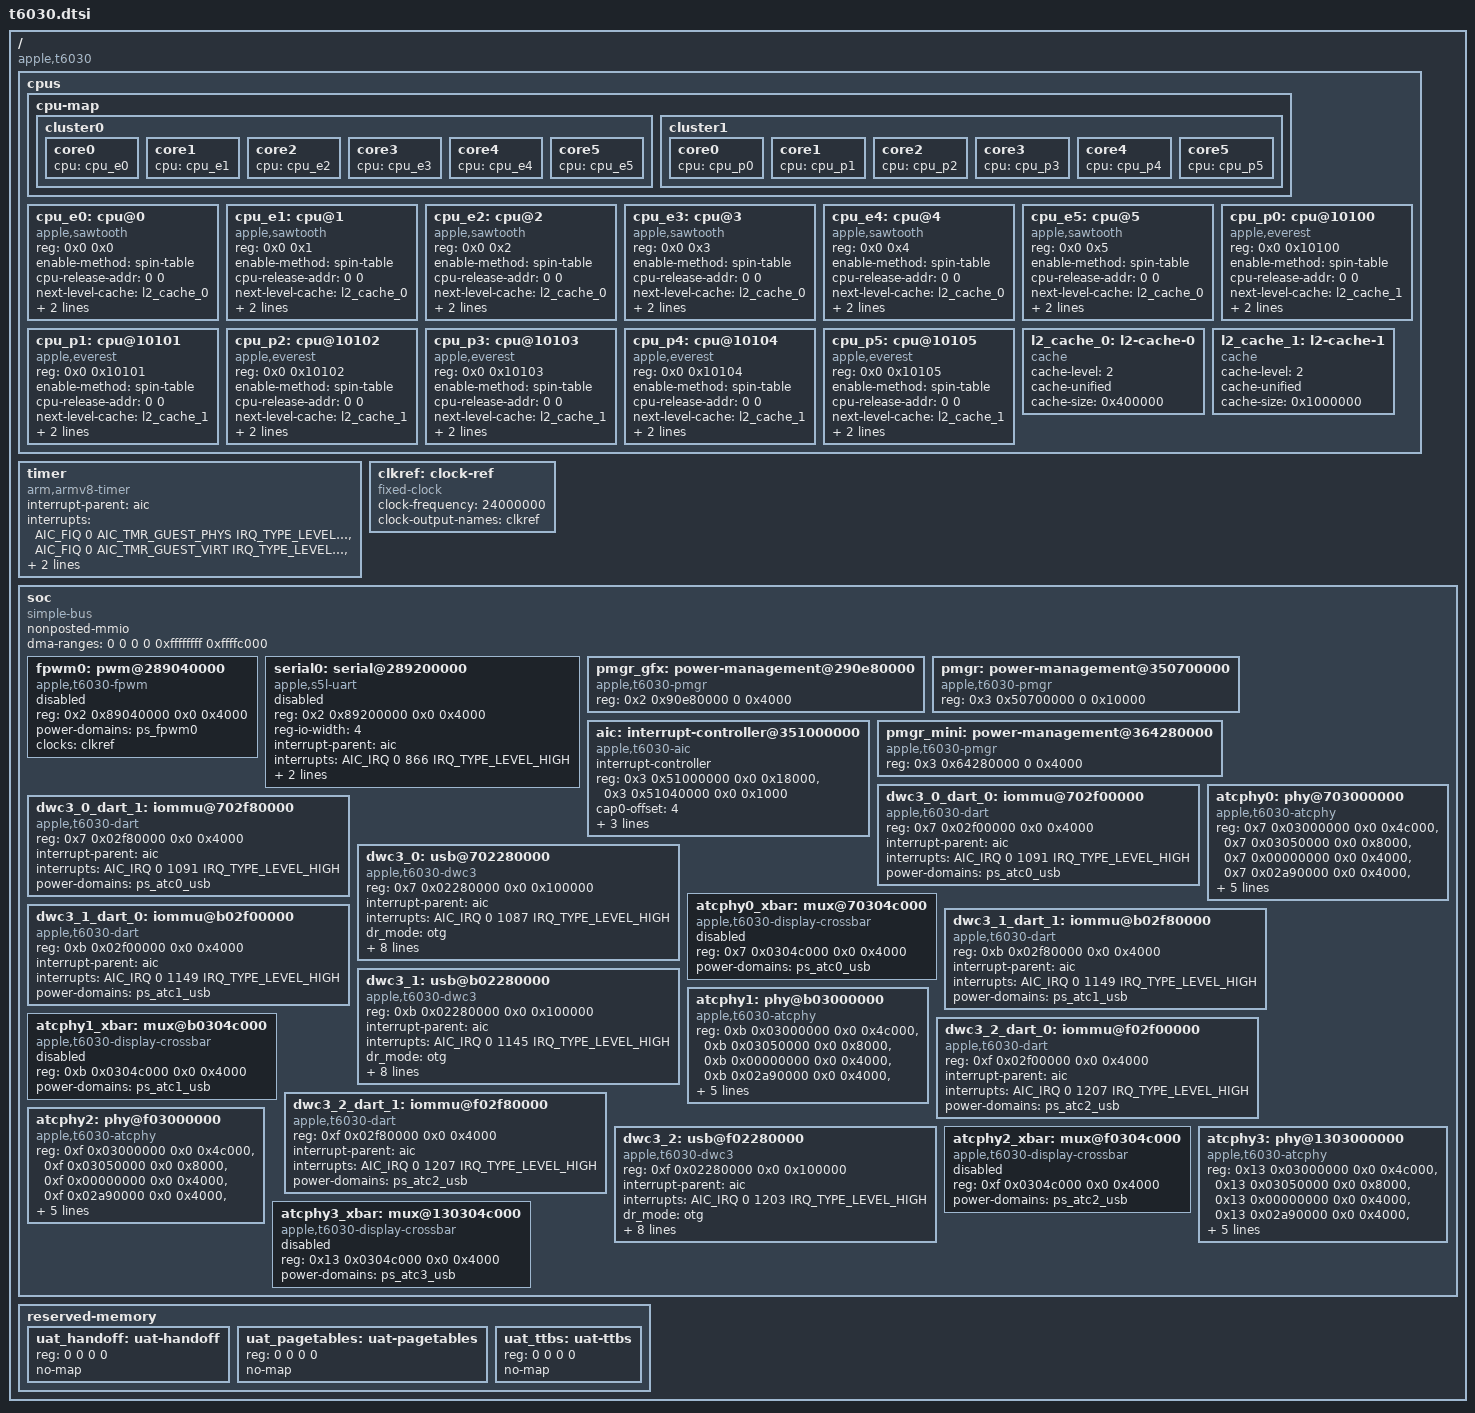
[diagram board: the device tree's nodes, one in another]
// SPDX-License-Identifier: GPL-2.0+ OR MIT
/*
 * Apple T6030 "M3 Pro" SoC
 *
 * Other names: H15J, "Lobos"
 *
 * Copyright The Asahi Linux Contributors
 */

#include <dt-bindings/interrupt-controller/apple-aic.h>
#include <dt-bindings/interrupt-controller/irq.h>
#include <dt-bindings/phy/phy.h>

#include "multi-die-cpp.h"

/ {
	compatible = "apple,t6030", "apple,arm-platform";

	#address-cells = <2>;
	#size-cells = <2>;

	cpus {
		#address-cells = <2>;
		#size-cells = <0>;

		cpu-map {
			cluster0 {
				core0 {
					cpu = <&cpu_e0>;
				};
				core1 {
					cpu = <&cpu_e1>;
				};
				core2 {
					cpu = <&cpu_e2>;
				};
				core3 {
					cpu = <&cpu_e3>;
				};
				core4 {
					cpu = <&cpu_e4>;
				};
				core5 {
					cpu = <&cpu_e5>;
				};
			};

			cluster1 {
				core0 {
					cpu = <&cpu_p0>;
				};
				core1 {
					cpu = <&cpu_p1>;
				};
				core2 {
					cpu = <&cpu_p2>;
				};
				core3 {
					cpu = <&cpu_p3>;
				};
				core4 {
					cpu = <&cpu_p4>;
				};
				core5 {
					cpu = <&cpu_p5>;
				};
			};
		};

		cpu_e0: cpu@0 {
			compatible = "apple,sawtooth";
			device_type = "cpu";
			reg = <0x0 0x0>;
			enable-method = "spin-table";
			cpu-release-addr = <0 0>; /* to be filled by loader */
			next-level-cache = <&l2_cache_0>;
			i-cache-size  = <0x20000>;
			d-cache-size = <0x10000>;
			//operating-points-v2 = <&sawtooth_opp>;
			//capacity-dmips-mhz = <756>;
			//performance-domains = <&cpufreq_e_die1>;
		};

		cpu_e1: cpu@1 {
			compatible = "apple,sawtooth";
			device_type = "cpu";
			reg = <0x0 0x1>;
			enable-method = "spin-table";
			cpu-release-addr = <0 0>; /* to be filled by loader */
			next-level-cache = <&l2_cache_0>;
			i-cache-size  = <0x20000>;
			d-cache-size = <0x10000>;
			//operating-points-v2 = <&sawtooth_opp>;
			//capacity-dmips-mhz = <756>;
			//performance-domains = <&cpufreq_e_die1>;
		};

		cpu_e2: cpu@2 {
			compatible = "apple,sawtooth";
			device_type = "cpu";
			reg = <0x0 0x2>;
			enable-method = "spin-table";
			cpu-release-addr = <0 0>; /* to be filled by loader */
			next-level-cache = <&l2_cache_0>;
			i-cache-size  = <0x20000>;
			d-cache-size = <0x10000>;
			//operating-points-v2 = <&sawtooth_opp>;
			//capacity-dmips-mhz = <756>;
			//performance-domains = <&cpufreq_e_die1>;
		};

		cpu_e3: cpu@3 {
			compatible = "apple,sawtooth";
			device_type = "cpu";
			reg = <0x0 0x3>;
			enable-method = "spin-table";
			cpu-release-addr = <0 0>; /* to be filled by loader */
			next-level-cache = <&l2_cache_0>;
			i-cache-size  = <0x20000>;
			d-cache-size = <0x10000>;
			//operating-points-v2 = <&sawtooth_opp>;
			//capacity-dmips-mhz = <756>;
			//performance-domains = <&cpufreq_e_die1>;
		};

		cpu_e4: cpu@4 {
			compatible = "apple,sawtooth";
			device_type = "cpu";
			reg = <0x0 0x4>;
			enable-method = "spin-table";
			cpu-release-addr = <0 0>; /* to be filled by loader */
			next-level-cache = <&l2_cache_0>;
			i-cache-size  = <0x20000>;
			d-cache-size = <0x10000>;
			//operating-points-v2 = <&sawtooth_opp>;
			//capacity-dmips-mhz = <756>;
			//performance-domains = <&cpufreq_e_die1>;
		};

		cpu_e5: cpu@5 {
			compatible = "apple,sawtooth";
			device_type = "cpu";
			reg = <0x0 0x5>;
			enable-method = "spin-table";
			cpu-release-addr = <0 0>; /* to be filled by loader */
			next-level-cache = <&l2_cache_0>;
			i-cache-size  = <0x20000>;
			d-cache-size = <0x10000>;
			//operating-points-v2 = <&sawtooth_opp>;
			//capacity-dmips-mhz = <756>;
			//performance-domains = <&cpufreq_e_die1>;
		};

		cpu_p0: cpu@10100 {
			compatible = "apple,everest";
			device_type = "cpu";
			reg = <0x0 0x10100>;
			enable-method = "spin-table";
			cpu-release-addr = <0 0>; /* to be filled by loader */
			next-level-cache = <&l2_cache_1>;
			i-cache-size  = <0x30000>;
			d-cache-size = <0x20000>;
			//operating-points-v2 = <&everest_opp>;
			//capacity-dmips-mhz = <756>;
			//performance-domains = <&cpufreq_e_die1>;
		};

		cpu_p1: cpu@10101 {
			compatible = "apple,everest";
			device_type = "cpu";
			reg = <0x0 0x10101>;
			enable-method = "spin-table";
			cpu-release-addr = <0 0>; /* to be filled by loader */
			next-level-cache = <&l2_cache_1>;
			i-cache-size  = <0x30000>;
			d-cache-size = <0x20000>;
			//operating-points-v2 = <&everest_opp>;
			//capacity-dmips-mhz = <756>;
			//performance-domains = <&cpufreq_e_die1>;
		};

		cpu_p2: cpu@10102 {
			compatible = "apple,everest";
			device_type = "cpu";
			reg = <0x0 0x10102>;
			enable-method = "spin-table";
			cpu-release-addr = <0 0>; /* to be filled by loader */
			next-level-cache = <&l2_cache_1>;
			i-cache-size  = <0x30000>;
			d-cache-size = <0x20000>;
			//operating-points-v2 = <&everest_opp>;
			//capacity-dmips-mhz = <756>;
			//performance-domains = <&cpufreq_e_die1>;
		};

		cpu_p3: cpu@10103 {
			compatible = "apple,everest";
			device_type = "cpu";
			reg = <0x0 0x10103>;
			enable-method = "spin-table";
			cpu-release-addr = <0 0>; /* to be filled by loader */
			next-level-cache = <&l2_cache_1>;
			i-cache-size  = <0x30000>;
			d-cache-size = <0x20000>;
			//operating-points-v2 = <&everest_opp>;
			//capacity-dmips-mhz = <756>;
			//performance-domains = <&cpufreq_e_die1>;
		};

		cpu_p4: cpu@10104 {
			compatible = "apple,everest";
			device_type = "cpu";
			reg = <0x0 0x10104>;
			enable-method = "spin-table";
			cpu-release-addr = <0 0>; /* to be filled by loader */
			next-level-cache = <&l2_cache_1>;
			i-cache-size  = <0x30000>;
			d-cache-size = <0x20000>;
			//operating-points-v2 = <&everest_opp>;
			//capacity-dmips-mhz = <756>;
			//performance-domains = <&cpufreq_e_die1>;
		};

		cpu_p5: cpu@10105 {
			compatible = "apple,everest";
			device_type = "cpu";
			reg = <0x0 0x10105>;
			enable-method = "spin-table";
			cpu-release-addr = <0 0>; /* to be filled by loader */
			next-level-cache = <&l2_cache_1>;
			i-cache-size  = <0x30000>;
			d-cache-size = <0x20000>;
			//operating-points-v2 = <&everest_opp>;
			//capacity-dmips-mhz = <756>;
			//performance-domains = <&cpufreq_e_die1>;
		};

		l2_cache_0: l2-cache-0 {
			compatible = "cache";
			cache-level = <2>;
			cache-unified;
			cache-size = <0x400000>;
		};

		l2_cache_1: l2-cache-1 {
			compatible = "cache";
			cache-level = <2>;
			cache-unified;
			cache-size = <0x1000000>;
		};
	};

	timer {
		compatible = "arm,armv8-timer";
		interrupt-parent = <&aic>;
		interrupt-names = "phys", "virt", "hyp-phys", "hyp-virt";
		interrupts = <AIC_FIQ 0 AIC_TMR_GUEST_PHYS IRQ_TYPE_LEVEL_HIGH>,
			     <AIC_FIQ 0 AIC_TMR_GUEST_VIRT IRQ_TYPE_LEVEL_HIGH>,
			     <AIC_FIQ 0 AIC_TMR_HV_PHYS IRQ_TYPE_LEVEL_HIGH>,
			     <AIC_FIQ 0 AIC_TMR_HV_VIRT IRQ_TYPE_LEVEL_HIGH>;
	};

	clkref: clock-ref {
		compatible = "fixed-clock";
		#clock-cells = <0>;
		clock-frequency = <24000000>;
		clock-output-names = "clkref";
	};

	soc {
		compatible = "simple-bus";
		#address-cells = <2>;
		#size-cells = <2>;

		ranges;
		nonposted-mmio;
		/* Required to get >32-bit DMA via DARTs */
		dma-ranges = <0 0 0 0 0xffffffff 0xffffc000>;

		fpwm0: pwm@289040000 {
			compatible = "apple,t6030-fpwm", "apple,s5l-fpwm";
			reg = <0x2 0x89040000 0x0 0x4000>;
			power-domains = <&ps_fpwm0>;
			clocks = <&clkref>;
			#pwm-cells = <2>;
			status = "disabled";
		};

		serial0: serial@289200000 {
			compatible = "apple,s5l-uart";
			reg = <0x2 0x89200000 0x0 0x4000>;
			reg-io-width = <4>;
			interrupt-parent = <&aic>;
			interrupts = <AIC_IRQ 0 866 IRQ_TYPE_LEVEL_HIGH>;
			/*
			* TODO: figure out the clocking properly, there may
			* be a third selectable clock.
			*/
			clocks = <&clkref>, <&clkref>;
			clock-names = "uart", "clk_uart_baud0";
			power-domains = <&ps_uart0>;
			status = "disabled";
		};

		pmgr_gfx: power-management@290e80000 {
			compatible = "apple,t6030-pmgr", "apple,pmgr", "syscon", "simple-mfd";
			#address-cells = <1>;
			#size-cells = <1>;
			reg = <0x2 0x90e80000 0 0x4000>;
		};

		pmgr: power-management@350700000 {
			compatible = "apple,t6030-pmgr", "apple,pmgr", "syscon", "simple-mfd";
			#address-cells = <1>;
			#size-cells = <1>;
			reg = <0x3 0x50700000 0 0x10000>;
		};

		aic: interrupt-controller@351000000 {
			compatible = "apple,t6030-aic", "apple,aic3";
			#interrupt-cells = <4>;
			interrupt-controller;
			reg = <0x3 0x51000000 0x0 0x18000>,
				  <0x3 0x51040000 0x0 0x1000>;
			reg-names = "core", "event";
			cap0-offset = <4>;
			maxnumirq-offset = <12>;
			config-offset = <0x10000>;
			power-domains = <&ps_aic>;
		};

		pmgr_mini: power-management@364280000 {
			compatible = "apple,t6030-pmgr", "apple,pmgr", "syscon", "simple-mfd";
			#address-cells = <1>;
			#size-cells = <1>;
			reg = <0x3 0x64280000 0 0x4000>;
		};

		dwc3_0_dart_0: iommu@702f00000 {
			compatible = "apple,t6030-dart", "apple,t8110-dart";
			reg = <0x7 0x02f00000 0x0 0x4000>;
			interrupt-parent = <&aic>;
			interrupts = <AIC_IRQ 0 1091 IRQ_TYPE_LEVEL_HIGH>;
			power-domains = <&ps_atc0_usb>;
			#iommu-cells = <1>;
		};

		dwc3_0_dart_1: iommu@702f80000 {
			compatible = "apple,t6030-dart", "apple,t8110-dart";
			reg = <0x7 0x02f80000 0x0 0x4000>;
			interrupt-parent = <&aic>;
			interrupts = <AIC_IRQ 0 1091 IRQ_TYPE_LEVEL_HIGH>;
			power-domains = <&ps_atc0_usb>;
			#iommu-cells = <1>;
		};

		dwc3_0: usb@702280000 {
			compatible = "apple,t6030-dwc3", "apple,dwc3", "snps,dwc3";
			reg = <0x7 0x02280000 0x0 0x100000>;
			interrupt-parent = <&aic>;
			interrupts = <AIC_IRQ 0 1087 IRQ_TYPE_LEVEL_HIGH>;
			dr_mode = "otg";
			usb-role-switch;
			role-switch-default-mode = "host";
			iommus = <&dwc3_0_dart_0 0>,
				<&dwc3_0_dart_1 1>;
			power-domains = <&ps_atc0_usb>;
			dma-coherent;
			resets = <&atcphy0>;
			maximum-speed = "high-speed";
			phys = <&atcphy0 PHY_TYPE_USB2>;
			phy-names = "usb2-phy";
		};

		atcphy0: phy@703000000 {
			compatible = "apple,t6030-atcphy", "apple,t8103-atcphy";
			reg = <0x7 0x03000000 0x0 0x4c000>,
				<0x7 0x03050000 0x0 0x8000>,
				<0x7 0x00000000 0x0 0x4000>,
				<0x7 0x02a90000 0x0 0x4000>,
				<0x7 0x02a84000 0x0 0x4000>;
			reg-names = "core", "lpdptx", "axi2af", "usb2phy",
				"pipehandler";

			#phy-cells = <1>;
			#reset-cells = <0>;

			orientation-switch;
			mode-switch;
			svid = <0xff01>, <0x8087>;
			power-domains = <&ps_atc0_usb>;
		};

		atcphy0_xbar: mux@70304c000 {
			compatible = "apple,t6030-display-crossbar";
			reg = <0x7 0x0304c000 0x0 0x4000>;
			#mux-control-cells = <1>;
			power-domains = <&ps_atc0_usb>;
			status = "disabled";
		};

		dwc3_1_dart_0: iommu@b02f00000 {
			compatible = "apple,t6030-dart", "apple,t8110-dart";
			reg = <0xb 0x02f00000 0x0 0x4000>;
			interrupt-parent = <&aic>;
			interrupts = <AIC_IRQ 0 1149 IRQ_TYPE_LEVEL_HIGH>;
			power-domains = <&ps_atc1_usb>;
			#iommu-cells = <1>;
		};

		dwc3_1_dart_1: iommu@b02f80000 {
			compatible = "apple,t6030-dart", "apple,t8110-dart";
			reg = <0xb 0x02f80000 0x0 0x4000>;
			interrupt-parent = <&aic>;
			interrupts = <AIC_IRQ 0 1149 IRQ_TYPE_LEVEL_HIGH>;
			power-domains = <&ps_atc1_usb>;
			#iommu-cells = <1>;
		};

		dwc3_1: usb@b02280000 {
			compatible = "apple,t6030-dwc3", "apple,dwc3", "snps,dwc3";
			reg = <0xb 0x02280000 0x0 0x100000>;
			interrupt-parent = <&aic>;
			interrupts = <AIC_IRQ 0 1145 IRQ_TYPE_LEVEL_HIGH>;
			dr_mode = "otg";
			usb-role-switch;
			role-switch-default-mode = "host";
			iommus = <&dwc3_1_dart_0 0>,
				<&dwc3_1_dart_1 1>;
			power-domains = <&ps_atc1_usb>;
			dma-coherent;
			resets = <&atcphy1>;
			maximum-speed = "high-speed";
			phys = <&atcphy1 PHY_TYPE_USB2>;
			phy-names = "usb2-phy";
		};

		atcphy1: phy@b03000000 {
			compatible = "apple,t6030-atcphy", "apple,t8103-atcphy";
			reg = <0xb 0x03000000 0x0 0x4c000>,
				<0xb 0x03050000 0x0 0x8000>,
				<0xb 0x00000000 0x0 0x4000>,
				<0xb 0x02a90000 0x0 0x4000>,
				<0xb 0x02a84000 0x0 0x4000>;
			reg-names = "core", "lpdptx", "axi2af", "usb2phy",
				"pipehandler";

			#phy-cells = <1>;
			#reset-cells = <0>;

			orientation-switch;
			mode-switch;
			svid = <0xff01>, <0x8087>;
			power-domains = <&ps_atc1_usb>;
		};

		atcphy1_xbar: mux@b0304c000 {
			compatible = "apple,t6030-display-crossbar";
			reg = <0xb 0x0304c000 0x0 0x4000>;
			#mux-control-cells = <1>;
			power-domains = <&ps_atc1_usb>;
			status = "disabled";
		};

		dwc3_2_dart_0: iommu@f02f00000 {
			compatible = "apple,t6030-dart", "apple,t8110-dart";
			reg = <0xf 0x02f00000 0x0 0x4000>;
			interrupt-parent = <&aic>;
			interrupts = <AIC_IRQ 0 1207 IRQ_TYPE_LEVEL_HIGH>;
			power-domains = <&ps_atc2_usb>;
			#iommu-cells = <1>;
		};

		dwc3_2_dart_1: iommu@f02f80000 {
			compatible = "apple,t6030-dart", "apple,t8110-dart";
			reg = <0xf 0x02f80000 0x0 0x4000>;
			interrupt-parent = <&aic>;
			interrupts = <AIC_IRQ 0 1207 IRQ_TYPE_LEVEL_HIGH>;
			power-domains = <&ps_atc2_usb>;
			#iommu-cells = <1>;
		};

		dwc3_2: usb@f02280000 {
			compatible = "apple,t6030-dwc3", "apple,dwc3", "snps,dwc3";
			reg = <0xf 0x02280000 0x0 0x100000>;
			interrupt-parent = <&aic>;
			interrupts = <AIC_IRQ 0 1203 IRQ_TYPE_LEVEL_HIGH>;
			dr_mode = "otg";
			usb-role-switch;
			role-switch-default-mode = "host";
			iommus = <&dwc3_2_dart_0 0>,
				<&dwc3_2_dart_1 1>;
			power-domains = <&ps_atc2_usb>;
			dma-coherent;
			resets = <&atcphy2>;
			maximum-speed = "high-speed";
			phys = <&atcphy2 PHY_TYPE_USB2>;
			phy-names = "usb2-phy";
		};

		atcphy2: phy@f03000000 {
			compatible = "apple,t6030-atcphy", "apple,t8103-atcphy";
			reg = <0xf 0x03000000 0x0 0x4c000>,
				<0xf 0x03050000 0x0 0x8000>,
				<0xf 0x00000000 0x0 0x4000>,
				<0xf 0x02a90000 0x0 0x4000>,
				<0xf 0x02a84000 0x0 0x4000>;
			reg-names = "core", "lpdptx", "axi2af", "usb2phy",
				"pipehandler";

			#phy-cells = <1>;
			#reset-cells = <0>;

			orientation-switch;
			mode-switch;
			svid = <0xff01>, <0x8087>;
			power-domains = <&ps_atc2_usb>;
		};

		atcphy2_xbar: mux@f0304c000 {
			compatible = "apple,t6030-display-crossbar";
			reg = <0xf 0x0304c000 0x0 0x4000>;
			#mux-control-cells = <1>;
			power-domains = <&ps_atc2_usb>;
			status = "disabled";
		};

		atcphy3: phy@1303000000 {
			compatible = "apple,t6030-atcphy", "apple,t8103-atcphy";
			reg = <0x13 0x03000000 0x0 0x4c000>,
				<0x13 0x03050000 0x0 0x8000>,
				<0x13 0x00000000 0x0 0x4000>,
				<0x13 0x02a90000 0x0 0x4000>,
				<0x13 0x02a84000 0x0 0x4000>;
			reg-names = "core", "lpdptx", "axi2af", "usb2phy",
				"pipehandler";

			#phy-cells = <1>;
			#reset-cells = <0>;

			orientation-switch;
			mode-switch;
			svid = <0xff01>, <0x8087>;
			power-domains = <&ps_atc3_usb>;
		};

		atcphy3_xbar: mux@130304c000 {
			compatible = "apple,t6030-display-crossbar";
			reg = <0x13 0x0304c000 0x0 0x4000>;
			#mux-control-cells = <1>;
			power-domains = <&ps_atc3_usb>;
			status = "disabled";
		};
	};

	reserved-memory {
		#address-cells = <2>;
		#size-cells = <2>;
		ranges;

		uat_handoff: uat-handoff {
			reg = <0 0 0 0>;
			no-map;
		};

		uat_pagetables: uat-pagetables {
			reg = <0 0 0 0>;
			no-map;
		};

		uat_ttbs: uat-ttbs {
			reg = <0 0 0 0>;
			no-map;
		};
	};
};

#define DIE
#define DIE_NO 0

#include "t603x-pmgr.dtsi"

#undef DIE
#undef DIE_NO
